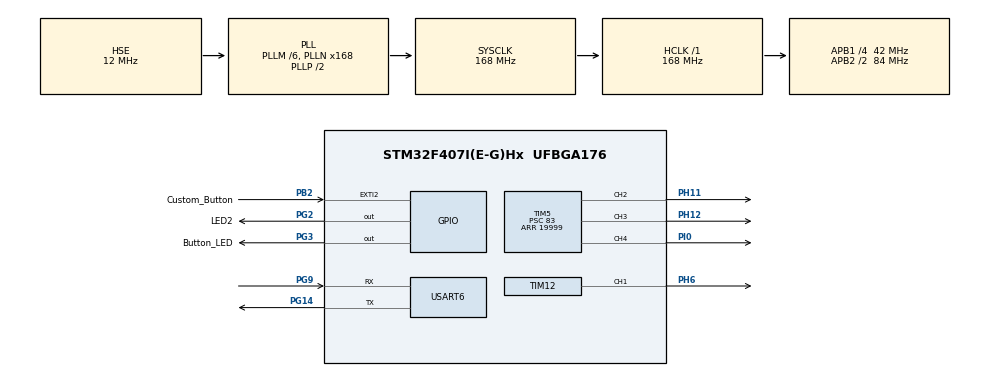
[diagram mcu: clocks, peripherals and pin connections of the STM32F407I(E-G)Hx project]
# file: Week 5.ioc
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Mcu.Family=STM32F4
Mcu.Name=STM32F407I(E-G)Hx
Mcu.Package=UFBGA176
NVIC.PriorityGroup=NVIC_PRIORITYGROUP_4
NVIC.USART6_IRQn=true\:0\:0\:false\:false\:true\:true\:true
PA13.Mode=Serial_Wire
PA13.Signal=SYS_JTMS-SWDIO
PA14.Mode=Serial_Wire
PA14.Signal=SYS_JTCK-SWCLK
PB2.GPIO_Label=Custom_Button
PB2.GPIO_ModeDefaultEXTI=GPIO_MODE_IT_RISING_FALLING
PB2.GPIO_PuPd=GPIO_PULLUP
PB2.Signal=GPXTI2
PG14.Mode=Asynchronous
PG14.Signal=USART6_TX
PG2.GPIO_Label=LED2
PG2.Signal=GPIO_Output
PG3.GPIO_Label=Button_LED
PG3.Signal=GPIO_Output
PG9.Mode=Asynchronous
PG9.Signal=USART6_RX
PH0-OSC_IN.Mode=HSE-External-Oscillator
PH0-OSC_IN.Signal=RCC_OSC_IN
PH1-OSC_OUT.Mode=HSE-External-Oscillator
PH1-OSC_OUT.Signal=RCC_OSC_OUT
PH11.Signal=S_TIM5_CH2
PH12.Signal=S_TIM5_CH3
PH6.Signal=S_TIM12_CH1
PI0.Signal=S_TIM5_CH4
ProjectManager.HeapSize=0x1000
ProjectManager.StackSize=0x400
ProjectManager.TargetToolchain=MDK-ARM V5.27
RCC.48MHZClocksFreq_Value=48000000
RCC.AHBFreq_Value=168000000
RCC.APB1CLKDivider=RCC_HCLK_DIV4
RCC.APB1Freq_Value=42000000
RCC.APB1TimFreq_Value=84000000
RCC.APB2CLKDivider=RCC_HCLK_DIV2
RCC.APB2Freq_Value=84000000
RCC.APB2TimFreq_Value=168000000
RCC.CortexFreq_Value=168000000
RCC.HCLKFreq_Value=168000000
RCC.HSE_VALUE=12000000
RCC.HSI_VALUE=16000000
RCC.LSE_VALUE=32768
RCC.PLLM=6
RCC.PLLN=168
RCC.PLLQ=7
RCC.PLLSourceVirtual=RCC_PLLSOURCE_HSE
RCC.SYSCLKFreq_VALUE=168000000
RCC.SYSCLKSource=RCC_SYSCLKSOURCE_PLLCLK
RCC.VCOOutputFreq_Value=336000000
SH.S_TIM12_CH1.0=TIM12_CH1,PWM Generation1 CH1
SH.S_TIM5_CH2.0=TIM5_CH2,PWM Generation2 CH2
SH.S_TIM5_CH3.0=TIM5_CH3,PWM Generation3 CH3
SH.S_TIM5_CH4.0=TIM5_CH4,PWM Generation4 CH4
TIM12.Channel-PWM\ Generation1\ CH1=TIM_CHANNEL_1
TIM12.Period=9999
TIM5.Channel-PWM\ Generation2\ CH2=TIM_CHANNEL_2
TIM5.Channel-PWM\ Generation3\ CH3=TIM_CHANNEL_3
TIM5.Channel-PWM\ Generation4\ CH4=TIM_CHANNEL_4
TIM5.Period=19999
TIM5.Prescaler=83
TIM5.Pulse-PWM\ Generation2\ CH2=2000
TIM5.Pulse-PWM\ Generation3\ CH3=2000
TIM5.Pulse-PWM\ Generation4\ CH4=2000
USART6.VirtualMode=VM_ASYNC
VP_TIM12_VS_ClockSourceINT.Mode=Internal
VP_TIM5_VS_ClockSourceINT.Mode=Internal
board=custom

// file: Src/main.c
/* USER CODE BEGIN Header */
/**
  ******************************************************************************
  * @file           : main.c
  * @brief          : Main program body
  ******************************************************************************
  * @attention
  *
  * <h2><center>&copy; Copyright (c) 2020 STMicroelectronics.
  * All rights reserved.</center></h2>
  *
  * This software component is licensed by ST under Ultimate Liberty license
  * SLA0044, the "License"; You may not use this file except in compliance with
  * the License. You may obtain a copy of the License at:
  *                             www.st.com/SLA0044
  *
  ******************************************************************************
  */
/* USER CODE END Header */

#include "main.h"
#include "tim.h"
#include "usart.h"
#include "gpio.h"

/* USER CODE BEGIN Includes */
#include "stdlib.h"
#include "time.h"
/* USER CODE END Includes */

void SystemClock_Config(void);
/* USER CODE BEGIN PFP */
/*
void USART6_IRQHandler(void)
{

    volatile uint8_t receive;
    //receive interrupt 接收中断
    if(huart6.Instance->SR & UART_FLAG_RXNE)
    {
        receive = huart6.Instance->DR;
        HAL_GPIO_TogglePin(LED2_GPIO_Port, LED2_Pin);

    }
    //idle interrupt 空闲中断
    else if(huart6.Instance->SR & UART_FLAG_IDLE)
    {
        receive = huart6.Instance->DR;
        HAL_GPIO_TogglePin(Custom_Button_GPIO_Port, Custom_Button_Pin);
    }

}
*/
/* USER CODE END PFP */

/* USER CODE BEGIN 0 */
unsigned char buf[4] = "000";
unsigned int change = 320;

unsigned int speed = 1500;

clock_t start;
clock_t end;

int count = 0;

int timedifference;

/* USER CODE END 0 */

int main(void)
{

  /* MCU Configuration--------------------------------------------------------*/

  /* Reset of all peripherals, Initializes the Flash interface and the Systick. */
  HAL_Init();

  /* Configure the system clock */
  SystemClock_Config();

  /* Initialize all configured peripherals */
  MX_GPIO_Init();
  MX_TIM12_Init();
  MX_TIM5_Init();
  MX_USART6_UART_Init();
  /* USER CODE BEGIN 2 */
	HAL_TIM_Base_Start_IT(&htim5);
	HAL_TIM_PWM_Start(&htim5, TIM_CHANNEL_2);
	HAL_TIM_PWM_Start(&htim5, TIM_CHANNEL_3);
	HAL_TIM_PWM_Start(&htim5, TIM_CHANNEL_4);

	//__HAL_TIM_SetCompare(&htim5, TIM_CHANNEL_2, 1500);
	//__HAL_TIM_SetCompare(&htim5, TIM_CHANNEL_3, 1500);
	__HAL_TIM_SetCompare(&htim5, TIM_CHANNEL_4, 1500);

	//HAL_UART_Receive(&huart6, buf, 4, 2000);
  /* USER CODE END 2 */
  start = clock();

  /* Infinite loop */
  /* USER CODE BEGIN WHILE */
  while (1)
  {
		//HAL_UART_Transmit(&huart6, buf, 5, 10);
		//HAL_Delay(1000);
    /* USER CODE END WHILE */

			/*
		HAL_UART_Receive(&huart6, buf, 4, 2000);
		count ++;

		if (*((unsigned int*)(buf)) > 0){

			if (*((unsigned int*)(buf)) >= change) {
				__HAL_TIM_SetCompare(&htim5, TIM_CHANNEL_4, 1700);
				HAL_GPIO_TogglePin(Custom_Button_GPIO_Port, Custom_Button_Pin);
			}
			else if (*((unsigned int*)(buf)) < change) {
				__HAL_TIM_SetCompare(&htim5, TIM_CHANNEL_4, 1300);
				HAL_GPIO_TogglePin(LED2_GPIO_Port, LED2_Pin);
			}
			else {
				__HAL_TIM_SetCompare(&htim5, TIM_CHANNEL_4, 1500);
			}
		}
		else {
			HAL_GPIO_TogglePin(Custom_Button_GPIO_Port, Custom_Button_Pin);
			__HAL_TIM_SetCompare(&htim5, TIM_CHANNEL_4, 1500);
		}
		memset(buf, 0, 4);
		//HAL_Delay(1);

		if (count >= 6000) {
			end = clock();
			timedifference = (end - start) * 1000 /CLOCKS_PER_SEC;
			sprintf(buf,"%d", 50);
			HAL_UART_Transmit(&huart6, buf, 5, 10);
		}
		*/

		HAL_UART_Transmit(&huart6, buf, 5, 10);
		HAL_Delay(2000);

  }
}

void SystemClock_Config(void)
{
  RCC_OscInitTypeDef RCC_OscInitStruct = {0};
  RCC_ClkInitTypeDef RCC_ClkInitStruct = {0};

  /** Configure the main internal regulator output voltage
  */
  __HAL_RCC_PWR_CLK_ENABLE();
  __HAL_PWR_VOLTAGESCALING_CONFIG(PWR_REGULATOR_VOLTAGE_SCALE1);
  /** Initializes the CPU, AHB and APB busses clocks
  */
  RCC_OscInitStruct.OscillatorType = RCC_OSCILLATORTYPE_HSE;
  RCC_OscInitStruct.HSEState = RCC_HSE_ON;
  RCC_OscInitStruct.PLL.PLLState = RCC_PLL_ON;
  RCC_OscInitStruct.PLL.PLLSource = RCC_PLLSOURCE_HSE;
  RCC_OscInitStruct.PLL.PLLM = 6;
  RCC_OscInitStruct.PLL.PLLN = 168;
  RCC_OscInitStruct.PLL.PLLP = RCC_PLLP_DIV2;
  RCC_OscInitStruct.PLL.PLLQ = 7;
  if (HAL_RCC_OscConfig(&RCC_OscInitStruct) != HAL_OK)
  {
    Error_Handler();
  }
  /** Initializes the CPU, AHB and APB busses clocks
  */
  RCC_ClkInitStruct.ClockType = RCC_CLOCKTYPE_HCLK|RCC_CLOCKTYPE_SYSCLK
                              |RCC_CLOCKTYPE_PCLK1|RCC_CLOCKTYPE_PCLK2;
  RCC_ClkInitStruct.SYSCLKSource = RCC_SYSCLKSOURCE_PLLCLK;
  RCC_ClkInitStruct.AHBCLKDivider = RCC_SYSCLK_DIV1;
  RCC_ClkInitStruct.APB1CLKDivider = RCC_HCLK_DIV4;
  RCC_ClkInitStruct.APB2CLKDivider = RCC_HCLK_DIV2;

  if (HAL_RCC_ClockConfig(&RCC_ClkInitStruct, FLASH_LATENCY_5) != HAL_OK)
  {
    Error_Handler();
  }
}

void Error_Handler(void)
{
}

/************************ (C) COPYRIGHT STMicroelectronics *****END OF FILE****/
